# iorx63n register map
Registers are 8-bit, access not given, no defined reset value unless marked. A register's access mark holds for its fields unless they carry their own. Addresses are absolute; registers are grouped by the start of their names; [hi:lo] are bit positions; {n}, {i} and the like mark numbered series; 'fields as' and 'values as' point back to an identical list.

## SFR (part 3 of 4)
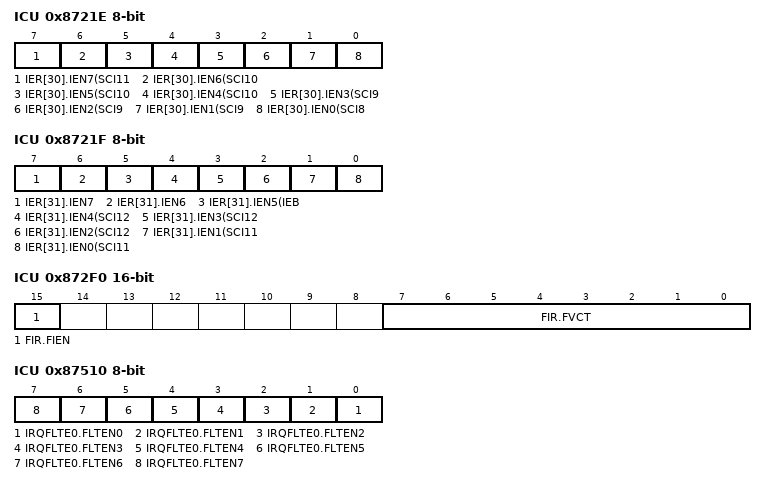
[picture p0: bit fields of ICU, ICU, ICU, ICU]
0x8721E ICU
  [7] IER[30].IEN7(SCI11,RXI11), [6] IER[30].IEN6(SCI10,TEI10), [5] IER[30].IEN5(SCI10,TXI10), [4] IER[30].IEN4(SCI10,RXI10), [3] IER[30].IEN3(SCI9,TEI9), [2] IER[30].IEN2(SCI9,TXI9), [1] IER[30].IEN1(SCI9,RXI9), [0] IER[30].IEN0(SCI8,TEI8)
0x8721F ICU
  [7] IER[31].IEN7, [6] IER[31].IEN6, [5] IER[31].IEN5(IEB,IEBINT), [4] IER[31].IEN4(SCI12,TEI12), [3] IER[31].IEN3(SCI12,TXI12), [2] IER[31].IEN2(SCI12,RXI12), [1] IER[31].IEN1(SCI11,TEI11), [0] IER[31].IEN0(SCI11,TXI11)
0x872E0 ICU
  [0] SWINTR.SWINT
0x872F0 ICU 16-bit
  [15] FIR.FIEN, [7:0] FIR.FVCT
0x87300 ICU
  [3:0] IPR[0](BSC,BUSERR).IPR
0x87301 ICU
  [3:0] IPR[1](FCU,FIFERR).IPR
0x87302 ICU
  [3:0] IPR[2](FCU,FRDYI).IPR
0x87303 ICU
  [3:0] IPR[3](ICU,SWINT).IPR
0x87304 ICU
  [3:0] IPR[4](CMT0,CMI0).IPR
0x87305 ICU
  [3:0] IPR[5](CMT1,CMI1).IPR
0x87306 ICU
  [3:0] IPR[6](CMT2,CMI2).IPR
0x87307 ICU
  [3:0] IPR[7](CMT3,CMI3).IPR
0x87308 ICU
  [3:0] IPR[8].IPR
0x87309 ICU
  [3:0] IPR[9].IPR
0x8730A ICU
  [3:0] IPR[10].IPR
0x8730B ICU
  [3:0] IPR[11].IPR
0x8730C ICU
  [3:0] IPR[12].IPR
0x8730D ICU
  [3:0] IPR[13].IPR
0x8730E ICU
  [3:0] IPR[14].IPR
0x8730F ICU
  [3:0] IPR[15].IPR
0x87310 ICU
  [3:0] IPR[16].IPR
0x87311 ICU
  [3:0] IPR[17].IPR
0x87312 ICU
  [3:0] IPR[18].IPR
0x87313 ICU
  [3:0] IPR[19].IPR
0x87314 ICU
  [3:0] IPR[20].IPR
0x87315 ICU
  [3:0] IPR[21].IPR
0x87316 ICU
  [3:0] IPR[22].IPR
0x87317 ICU
  [3:0] IPR[23].IPR
0x87318 ICU
  [3:0] IPR[24].IPR
0x87319 ICU
  [3:0] IPR[25].IPR
0x8731A ICU
  [3:0] IPR[26].IPR
0x8731B ICU
  [3:0] IPR[27].IPR
0x8731C ICU
  [3:0] IPR[28].IPR
0x8731D ICU
  [3:0] IPR[29].IPR
0x8731E ICU
  [3:0] IPR[30].IPR
0x8731F ICU
  [3:0] IPR[31].IPR
0x87320 ICU
  [3:0] IPR[32](ETHER,EINT).IPR
0x87321 ICU
  [3:0] IPR[33](USB0,D0FIFO0).IPR
0x87322 ICU
  [3:0] IPR[34](USB0,D1FIFO0).IPR
0x87323 ICU
  [3:0] IPR[35](USB0,USBI0).IPR
0x87324 ICU
  [3:0] IPR[36](USB1,D0FIFO1).IPR
0x87325 ICU
  [3:0] IPR[37](USB1,D1FIFO1).IPR
0x87326 ICU
  [3:0] IPR[38](USB1,USBI1).IPR
0x87327 ICU
  [3:0] IPR[39](RSPI0,SPRI0...).IPR
0x87328 ICU
  [3:0] IPR[40].IPR
0x87329 ICU
  [3:0] IPR[41].IPR
0x8732A ICU
  [3:0] IPR[42](RSPI1,SPRI1...).IPR
0x8732B ICU
  [3:0] IPR[43].IPR
0x8732C ICU
  [3:0] IPR[44].IPR
0x8732D ICU
  [3:0] IPR[45](RSPI2,SPRI2...).IPR
0x8732E ICU
  [3:0] IPR[46].IPR
0x8732F ICU
  [3:0] IPR[47].IPR
0x87330 ICU
  [3:0] IPR[48](CAN0,RXF0...).IPR
0x87331 ICU
  [3:0] IPR[49].IPR
0x87332 ICU
  [3:0] IPR[50].IPR
0x87333 ICU
  [3:0] IPR[51].IPR
0x87334 ICU
  [3:0] IPR[52](CAN1,RXF1...).IPR
0x87335 ICU
  [3:0] IPR[53].IPR
0x87336 ICU
  [3:0] IPR[54].IPR
0x87337 ICU
  [3:0] IPR[55].IPR
0x87338 ICU
  [3:0] IPR[56](CAN2,RXF2...).IPR
0x87339 ICU
  [3:0] IPR[57].IPR
0x8733A ICU
  [3:0] IPR[58].IPR
0x8733B ICU
  [3:0] IPR[59].IPR
0x8733C ICU
  [3:0] IPR[60].IPR
0x8733D ICU
  [3:0] IPR[61].IPR
0x8733E ICU
  [3:0] IPR[62](RTC,CUP).IPR
0x8733F ICU
  [3:0] IPR[63].IPR
0x87340 ICU
  [3:0] IPR[64](ICU,IRQ0).IPR
0x87341 ICU
  [3:0] IPR[65](ICU,IRQ1).IPR
0x87342 ICU
  [3:0] IPR[66](ICU,IRQ2).IPR
0x87343 ICU
  [3:0] IPR[67](ICU,IRQ3).IPR
0x87344 ICU
  [3:0] IPR[68](ICU,IRQ4).IPR
0x87345 ICU
  [3:0] IPR[69](ICU,IRQ5).IPR
0x87346 ICU
  [3:0] IPR[70](ICU,IRQ6).IPR
0x87347 ICU
  [3:0] IPR[71](ICU,IRQ7).IPR
0x87348 ICU
  [3:0] IPR[72](ICU,IRQ8).IPR
0x87349 ICU
  [3:0] IPR[73](ICU,IRQ9).IPR
0x8734A ICU
  [3:0] IPR[74](ICU,IRQ10).IPR
0x8734B ICU
  [3:0] IPR[75](ICU,IRQ11).IPR
0x8734C ICU
  [3:0] IPR[76](ICU,IRQ12).IPR
0x8734D ICU
  [3:0] IPR[77](ICU,IRQ13).IPR
0x8734E ICU
  [3:0] IPR[78](ICU,IRQ14).IPR
0x8734F ICU
  [3:0] IPR[79](ICU,IRQ15).IPR
0x87350 ICU
  [3:0] IPR[80].IPR
0x87351 ICU
  [3:0] IPR[81].IPR
0x87352 ICU
  [3:0] IPR[82].IPR
0x87353 ICU
  [3:0] IPR[83].IPR
0x87354 ICU
  [3:0] IPR[84].IPR
0x87355 ICU
  [3:0] IPR[85].IPR
0x87356 ICU
  [3:0] IPR[86].IPR
0x87357 ICU
  [3:0] IPR[87].IPR
0x87358 ICU
  [3:0] IPR[88].IPR
0x87359 ICU
  [3:0] IPR[89].IPR
0x8735A ICU
  [3:0] IPR[90](USB,USBR0).IPR
0x8735B ICU
  [3:0] IPR[91](USB,USBR1).IPR
0x8735C ICU
  [3:0] IPR[92](RTC,ALM).IPR
0x8735D ICU
  [3:0] IPR[93](RTC,PRD).IPR
0x8735E ICU
  [3:0] IPR[94].IPR
0x8735F ICU
  [3:0] IPR[95].IPR
0x87360 ICU
  [3:0] IPR[96].IPR
0x87361 ICU
  [3:0] IPR[97].IPR
0x87362 ICU
  [3:0] IPR[98](AD,ADI0).IPR
0x87363 ICU
  [3:0] IPR[99].IPR
0x87364 ICU
  [3:0] IPR[100].IPR
0x87365 ICU
  [3:0] IPR[101].IPR
0x87366 ICU
  [3:0] IPR[102](S12AD,S12ADI0).IPR
0x87367 ICU
  [3:0] IPR[103].IPR
0x87368 ICU
  [3:0] IPR[104].IPR
0x87369 ICU
  [3:0] IPR[105].IPR
0x8736A ICU
  [3:0] IPR[106](ICU,GROUP0).IPR
0x8736B ICU
  [3:0] IPR[107](ICU,GROUP1).IPR
0x8736C ICU
  [3:0] IPR[108](ICU,GROUP2).IPR
0x8736D ICU
  [3:0] IPR[109](ICU,GROUP3).IPR
0x8736E ICU
  [3:0] IPR[110](ICU,GROUP4).IPR
0x8736F ICU
  [3:0] IPR[111](ICU,GROUP5).IPR
0x87370 ICU
  [3:0] IPR[112](ICU,GROUP6).IPR
0x87371 ICU
  [3:0] IPR[113].IPR
0x87372 ICU
  [3:0] IPR[114](ICU,GROUP12).IPR
0x87373 ICU
  [3:0] IPR[115].IPR
0x87374 ICU
  [3:0] IPR[116].IPR
0x87375 ICU
  [3:0] IPR[117].IPR
0x87376 ICU
  [3:0] IPR[118].IPR
0x87377 ICU
  [3:0] IPR[119].IPR
0x87378 ICU
  [3:0] IPR[120].IPR
0x87379 ICU
  [3:0] IPR[121].IPR
0x8737A ICU
  [3:0] IPR[122](SCI12,SCIX0...).IPR
0x8737B ICU
  [3:0] IPR[123].IPR
0x8737C ICU
  [3:0] IPR[124].IPR
0x8737D ICU
  [3:0] IPR[125].IPR
0x8737E ICU
  [3:0] IPR[126](TPU0,TGI0A...).IPR
0x8737F ICU
  [3:0] IPR[127].IPR
0x87380 ICU
  [3:0] IPR[128].IPR
0x87381 ICU
  [3:0] IPR[129].IPR
0x87382 ICU
  [3:0] IPR[130](TPU1,TGI1A...).IPR
0x87383 ICU
  [3:0] IPR[131].IPR
0x87384 ICU
  [3:0] IPR[132](TPU2,TGI2A...).IPR
0x87385 ICU
  [3:0] IPR[133].IPR
0x87386 ICU
  [3:0] IPR[134](TPU3,TGI3A...).IPR
0x87387 ICU
  [3:0] IPR[135].IPR
0x87388 ICU
  [3:0] IPR[136].IPR
0x87389 ICU
  [3:0] IPR[137].IPR
0x8738A ICU
  [3:0] IPR[138](TPU4,TGI4A...).IPR
0x8738B ICU
  [3:0] IPR[139].IPR
0x8738C ICU
  [3:0] IPR[140](TPU5,TGI5A...).IPR
0x8738D ICU
  [3:0] IPR[141].IPR
0x8738E ICU
  [3:0] IPR[142](TPU6,TGI6A...).IPR
0x8738F ICU
  [3:0] IPR[143].IPR
0x87390 ICU
  [3:0] IPR[144].IPR
0x87391 ICU
  [3:0] IPR[145].IPR
0x87392 ICU
  [3:0] IPR[146](MTU0,TGIE0...).IPR
0x87393 ICU
  [3:0] IPR[147].IPR
0x87394 ICU
  [3:0] IPR[148](TPU7,TGI7A...).IPR
0x87395 ICU
  [3:0] IPR[149].IPR
0x87396 ICU
  [3:0] IPR[150](TPU8,TGI8A...).IPR
0x87397 ICU
  [3:0] IPR[151].IPR
0x87398 ICU
  [3:0] IPR[152](TPU9,TGI9A...).IPR
0x87399 ICU
  [3:0] IPR[153].IPR
0x8739A ICU
  [3:0] IPR[154].IPR
0x8739B ICU
  [3:0] IPR[155].IPR
0x8739C ICU
  [3:0] IPR[156](TPU10,TGI10A...).IPR
0x8739D ICU
  [3:0] IPR[157].IPR
0x8739E ICU
  [3:0] IPR[158].IPR
0x8739F ICU
  [3:0] IPR[159].IPR
0x873A0 ICU
  [3:0] IPR[160](MTU4,TCIV4).IPR
0x873A1 ICU
  [3:0] IPR[161](MTU5,TGIU5...).IPR
0x873A2 ICU
  [3:0] IPR[162].IPR
0x873A3 ICU
  [3:0] IPR[163].IPR
0x873A4 ICU
  [3:0] IPR[164](TPU11,TGI11A...).IPR
0x873A5 ICU
  [3:0] IPR[165].IPR
0x873A6 ICU
  [3:0] IPR[166](POE,OEI1...).IPR
0x873A7 ICU
  [3:0] IPR[167].IPR
0x873A8 ICU
  [3:0] IPR[168].IPR
0x873A9 ICU
  [3:0] IPR[169].IPR
0x873AA ICU
  [3:0] IPR[170](TMR0,CMIA0...).IPR
0x873AB ICU
  [3:0] IPR[171].IPR
0x873AC ICU
  [3:0] IPR[172].IPR
0x873AD ICU
  [3:0] IPR[173](TMR1,CMIA1...).IPR
0x873AE ICU
  [3:0] IPR[174].IPR
0x873AF ICU
  [3:0] IPR[175].IPR
0x873B0 ICU
  [3:0] IPR[176](TMR2,CMIA2...).IPR
0x873B1 ICU
  [3:0] IPR[177].IPR
0x873B2 ICU
  [3:0] IPR[178].IPR
0x873B3 ICU
  [3:0] IPR[179](TMR3,CMIA3...).IPR
0x873B4 ICU
  [3:0] IPR[180].IPR
0x873B5 ICU
  [3:0] IPR[181].IPR
0x873B6 ICU
  [3:0] IPR[182](RIIC0,EEI0).IPR
0x873B7 ICU
  [3:0] IPR[183](RIIC0,RXI0).IPR
0x873B8 ICU
  [3:0] IPR[184](RIIC0,TXI0).IPR
0x873B9 ICU
  [3:0] IPR[185](RIIC0,TEI0).IPR
0x873BA ICU
  [3:0] IPR[186](RIIC1,EEI1).IPR
0x873BB ICU
  [3:0] IPR[187](RIIC1,RXI1).IPR
0x873BC ICU
  [3:0] IPR[188](RIIC1,TXI1).IPR
0x873BD ICU
  [3:0] IPR[189](RIIC1,TEI1).IPR
0x873BE ICU
  [3:0] IPR[190](RIIC2,EEI2).IPR
0x873BF ICU
  [3:0] IPR[191](RIIC2,RXI2).IPR
0x873C0 ICU
  [3:0] IPR[192](RIIC2,TXI2).IPR
0x873C1 ICU
  [3:0] IPR[193](RIIC2,TEI2).IPR
0x873C2 ICU
  [3:0] IPR[194](RIIC3,EEI3).IPR
0x873C3 ICU
  [3:0] IPR[195](RIIC3,RXI3).IPR
0x873C4 ICU
  [3:0] IPR[196](RIIC3,TXI3).IPR
0x873C5 ICU
  [3:0] IPR[197](RIIC3,TEI3).IPR
0x873C6 ICU
  [3:0] IPR[198](DMAC,DMAC0I).IPR
0x873C7 ICU
  [3:0] IPR[199](DMAC,DMAC1I).IPR
0x873C8 ICU
  [3:0] IPR[200](DMAC,DMAC2I).IPR
0x873C9 ICU
  [3:0] IPR[201](DMAC,DMAC3I).IPR
0x873CA ICU
  [3:0] IPR[202](EXDMAC,EXDMAC0I).IPR
0x873CB ICU
  [3:0] IPR[203](EXDMAC,EXDMAC1I).IPR
0x873CC ICU
  [3:0] IPR[204].IPR
0x873CD ICU
  [3:0] IPR[205].IPR
0x873CE ICU
  [3:0] IPR[206].IPR
0x873CF ICU
  [3:0] IPR[207].IPR
0x873D0 ICU
  [3:0] IPR[208].IPR
0x873D1 ICU
  [3:0] IPR[209].IPR
0x873D2 ICU
  [3:0] IPR[210].IPR
0x873D3 ICU
  [3:0] IPR[211].IPR
0x873D4 ICU
  [3:0] IPR[212].IPR
0x873D5 ICU
  [3:0] IPR[213].IPR
0x873D6 ICU
  [3:0] IPR[214](SCI0,RXI0...).IPR
0x873D7 ICU
  [3:0] IPR[215].IPR
0x873D8 ICU
  [3:0] IPR[216].IPR
0x873D9 ICU
  [3:0] IPR[217](SCI1,RXI1...).IPR
0x873DA ICU
  [3:0] IPR[218].IPR
0x873DB ICU
  [3:0] IPR[219].IPR
0x873DC ICU
  [3:0] IPR[220](SCI2,RXI2...).IPR
0x873DD ICU
  [3:0] IPR[221].IPR
0x873DE ICU
  [3:0] IPR[222].IPR
0x873DF ICU
  [3:0] IPR[223](SCI3,RXI3...).IPR
0x873E0 ICU
  [3:0] IPR[224].IPR
0x873E1 ICU
  [3:0] IPR[225].IPR
0x873E2 ICU
  [3:0] IPR[226](SCI4,RXI4...).IPR
0x873E3 ICU
  [3:0] IPR[227].IPR
0x873E4 ICU
  [3:0] IPR[228].IPR
0x873E5 ICU
  [3:0] IPR[229](SCI5,RXI5...).IPR
0x873E6 ICU
  [3:0] IPR[230].IPR
0x873E7 ICU
  [3:0] IPR[231].IPR
0x873E8 ICU
  [3:0] IPR[232](SCI6,RXI6...).IPR
0x873E9 ICU
  [3:0] IPR[233].IPR
0x873EA ICU
  [3:0] IPR[234].IPR
0x873EB ICU
  [3:0] IPR[235](SCI7,RXI7...).IPR
0x873EC ICU
  [3:0] IPR[236].IPR
0x873ED ICU
  [3:0] IPR[237].IPR
0x873EE ICU
  [3:0] IPR[238](SCI8,RXI8...).IPR
0x873EF ICU
  [3:0] IPR[239].IPR
0x873F0 ICU
  [3:0] IPR[240].IPR
0x873F1 ICU
  [3:0] IPR[241](SCI9,RXI9...).IPR
0x873F2 ICU
  [3:0] IPR[242].IPR
0x873F3 ICU
  [3:0] IPR[243].IPR
0x873F4 ICU
  [3:0] IPR[244](SCI10,RXI10...).IPR
0x873F5 ICU
  [3:0] IPR[245].IPR
0x873F6 ICU
  [3:0] IPR[246].IPR
0x873F7 ICU
  [3:0] IPR[247](SCI11,RXI11...).IPR
0x873F8 ICU
  [3:0] IPR[248].IPR
0x873F9 ICU
  [3:0] IPR[249].IPR
0x873FA ICU
  [3:0] IPR[250](SCI12,RXI12...).IPR
0x873FB ICU
  [3:0] IPR[251].IPR
0x873FC ICU
  [3:0] IPR[252].IPR
0x873FD ICU
  [3:0] IPR[253](IEB,IEBINT).IPR
0x87400 ICU
  [7:0] DMRSR0.DMRS
0x87404 ICU
  [7:0] DMRSR1.DMRS
0x87408 ICU
  [7:0] DMRSR2.DMRS
0x8740C ICU
  [7:0] DMRSR3.DMRS
0x87500 ICU
  [3:2] IRQCR[0].IRQMD
0x87501 ICU
  [3:2] IRQCR[1].IRQMD
0x87502 ICU
  [3:2] IRQCR[2].IRQMD
0x87503 ICU
  [3:2] IRQCR[3].IRQMD
0x87504 ICU
  [3:2] IRQCR[4].IRQMD
0x87505 ICU
  [3:2] IRQCR[5].IRQMD
0x87506 ICU
  [3:2] IRQCR[6].IRQMD
0x87507 ICU
  [3:2] IRQCR[7].IRQMD
0x87508 ICU
  [3:2] IRQCR[8].IRQMD
0x87509 ICU
  [3:2] IRQCR[9].IRQMD
0x8750A ICU
  [3:2] IRQCR[10].IRQMD
0x8750B ICU
  [3:2] IRQCR[11].IRQMD
0x8750C ICU
  [3:2] IRQCR[12].IRQMD
0x8750D ICU
  [3:2] IRQCR[13].IRQMD
0x8750E ICU
  [3:2] IRQCR[14].IRQMD
0x8750F ICU
  [3:2] IRQCR[15].IRQMD
0x87510 ICU
  [n] IRQFLTE0.FLTEN{n} (n=0..7)
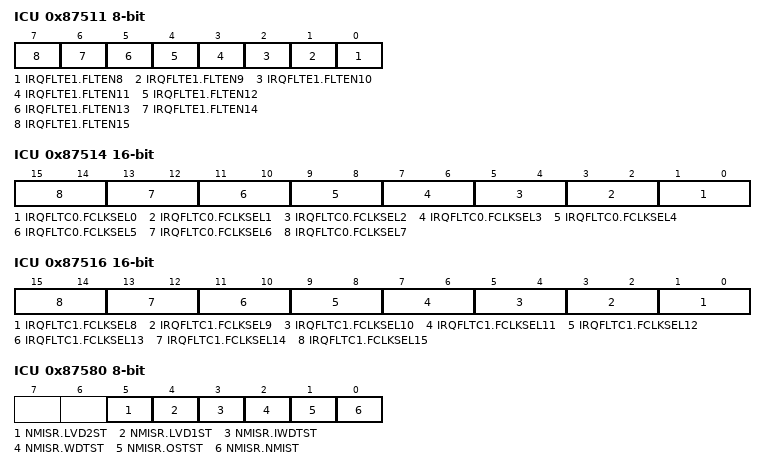
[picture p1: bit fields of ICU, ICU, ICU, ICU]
0x87511 ICU
  [n-8] IRQFLTE1.FLTEN{n} (n=8..15)
0x87514 ICU 16-bit
  [2n+1:2n] IRQFLTC0.FCLKSEL{n} (n=0..7)
0x87516 ICU 16-bit
  [2n-15:2n-16] IRQFLTC1.FCLKSEL{n} (n=8..15)
0x87580 ICU
  [5] NMISR.LVD2ST, [4] NMISR.LVD1ST, [3] NMISR.IWDTST, [2] NMISR.WDTST, [1] NMISR.OSTST, [0] NMISR.NMIST
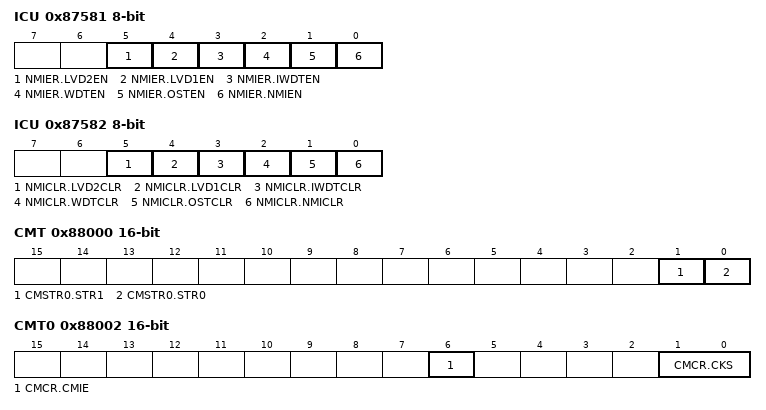
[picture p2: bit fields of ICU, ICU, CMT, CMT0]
0x87581 ICU
  [5] NMIER.LVD2EN, [4] NMIER.LVD1EN, [3] NMIER.IWDTEN, [2] NMIER.WDTEN, [1] NMIER.OSTEN, [0] NMIER.NMIEN
0x87582 ICU
  [5] NMICLR.LVD2CLR, [4] NMICLR.LVD1CLR, [3] NMICLR.IWDTCLR, [2] NMICLR.WDTCLR, [1] NMICLR.OSTCLR, [0] NMICLR.NMICLR
0x87583 ICU
  [3] NMICR.NMIMD
0x87590 ICU
  [0] NMIFLTE.NFLTEN
0x87594 ICU
  [1:0] NMIFLTC.NFCLKSEL
0x88000 CMT 16-bit
  [1] CMSTR0.STR1, [0] CMSTR0.STR0
0x88002 CMT0 16-bit
  [6] CMCR.CMIE, [1:0] CMCR.CKS
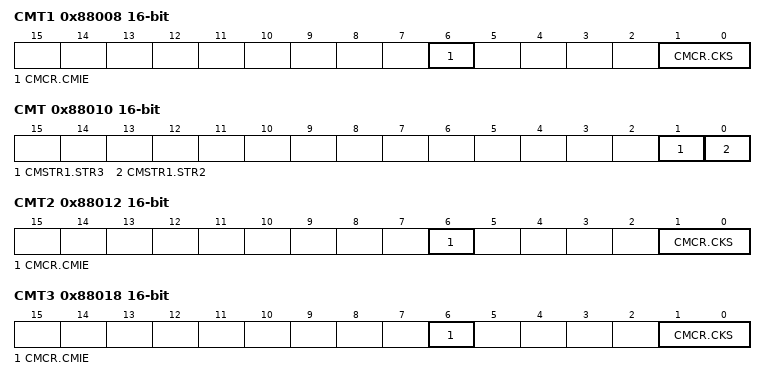
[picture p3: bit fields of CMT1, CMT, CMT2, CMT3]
0x88008 CMT1 16-bit
  [6] CMCR.CMIE, [1:0] CMCR.CKS
0x88010 CMT 16-bit
  [1] CMSTR1.STR3, [0] CMSTR1.STR2
0x88012 CMT2 16-bit
  [6] CMCR.CMIE, [1:0] CMCR.CKS
0x88018 CMT3 16-bit
  [6] CMCR.CMIE, [1:0] CMCR.CKS
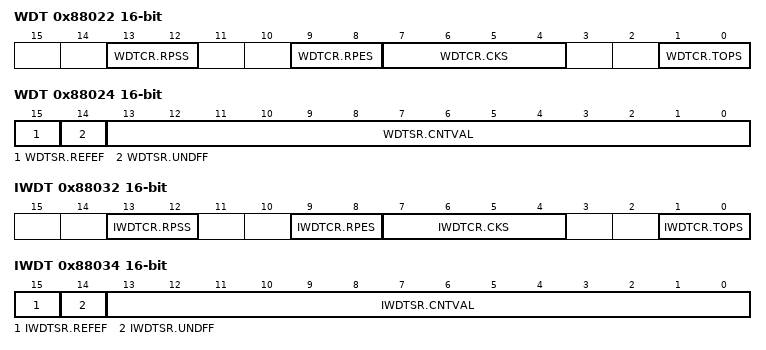
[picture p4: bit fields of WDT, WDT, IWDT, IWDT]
0x88022 WDT 16-bit
  [13:12] WDTCR.RPSS, [9:8] WDTCR.RPES, [7:4] WDTCR.CKS, [1:0] WDTCR.TOPS
0x88024 WDT 16-bit
  [15] WDTSR.REFEF, [14] WDTSR.UNDFF, [13:0] WDTSR.CNTVAL
0x88026 WDT
  [7] WDTRCR.RSTIRQS
0x88032 IWDT 16-bit
  [13:12] IWDTCR.RPSS, [9:8] IWDTCR.RPES, [7:4] IWDTCR.CKS, [1:0] IWDTCR.TOPS
0x88034 IWDT 16-bit
  [15] IWDTSR.REFEF, [14] IWDTSR.UNDFF, [13:0] IWDTSR.CNTVAL
0x88036 IWDT
  [7] IWDTRCR.RSTIRQS
0x88038 IWDT
  [7] IWDTCSTPR.SLCSTP
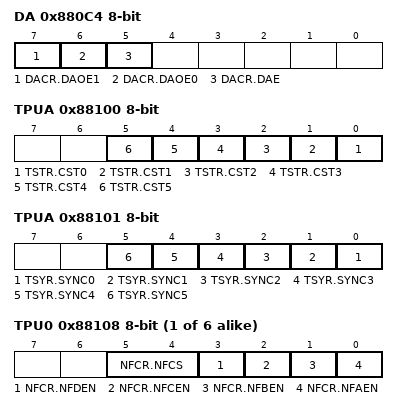
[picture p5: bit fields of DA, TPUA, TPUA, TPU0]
0x880C4 DA
  [7] DACR.DAOE1, [6] DACR.DAOE0, [5] DACR.DAE
0x880C5 DA
  [7] DADPR.DPSEL
0x880C6 DA
  [7] DAADSCR.DAADST
0x88100 TPUA
  [n] TSTR.CST{n} (n=0..5)
0x88101 TPUA
  [n] TSYR.SYNC{n} (n=0..5)
{0x88108+i} TPU{i} (i=0..5)
  [5:4] NFCR.NFCS, [3] NFCR.NFDEN, [2] NFCR.NFCEN, [1] NFCR.NFBEN, [0] NFCR.NFAEN
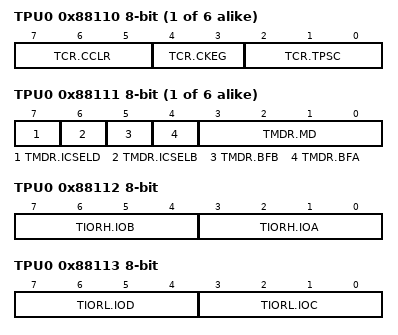
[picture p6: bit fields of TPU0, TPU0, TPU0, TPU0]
{0x88110+0x10*i} TPU{i} (i=0..5)
  [7:5] TCR.CCLR, [4:3] TCR.CKEG, [2:0] TCR.TPSC
{0x88111+0x10*i} TPU{i} (i=0..5)
  [7] TMDR.ICSELD, [6] TMDR.ICSELB, [5] TMDR.BFB, [4] TMDR.BFA, [3:0] TMDR.MD
0x88112 TPU0
  [7:4] TIORH.IOB, [3:0] TIORH.IOA
0x88113 TPU0
  [7:4] TIORL.IOD, [3:0] TIORL.IOC
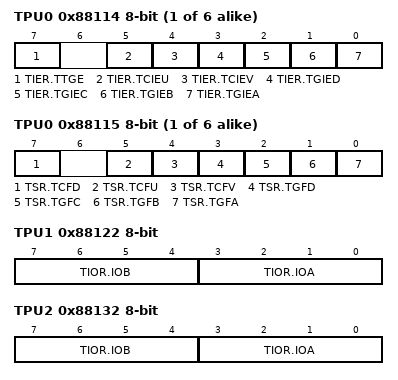
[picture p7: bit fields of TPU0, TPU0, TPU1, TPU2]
{0x88114+0x10*i} TPU{i} (i=0..5)
  [7] TIER.TTGE, [5] TIER.TCIEU, [4] TIER.TCIEV, [3] TIER.TGIED, [2] TIER.TGIEC, [1] TIER.TGIEB, [0] TIER.TGIEA
{0x88115+0x10*i} TPU{i} (i=0..5)
  [7] TSR.TCFD, [5] TSR.TCFU, [4] TSR.TCFV, [3] TSR.TGFD, [2] TSR.TGFC, [1] TSR.TGFB, [0] TSR.TGFA
0x88122 TPU1
  [7:4] TIOR.IOB, [3:0] TIOR.IOA
0x88132 TPU2
  [7:4] TIOR.IOB, [3:0] TIOR.IOA
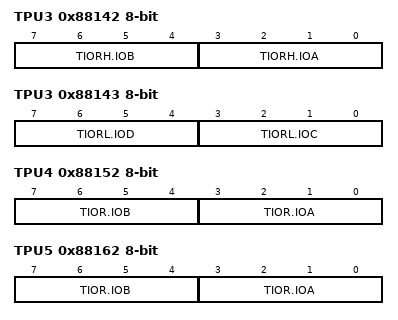
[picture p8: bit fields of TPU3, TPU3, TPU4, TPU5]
0x88142 TPU3
  [7:4] TIORH.IOB, [3:0] TIORH.IOA
0x88143 TPU3
  [7:4] TIORL.IOD, [3:0] TIORL.IOC
0x88152 TPU4
  [7:4] TIOR.IOB, [3:0] TIOR.IOA
0x88162 TPU5
  [7:4] TIOR.IOB, [3:0] TIOR.IOA
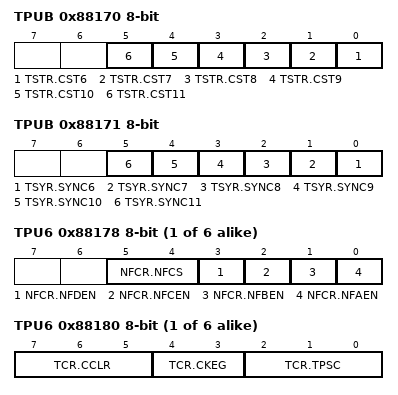
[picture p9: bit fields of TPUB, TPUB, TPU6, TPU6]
0x88170 TPUB
  [n-6] TSTR.CST{n} (n=6..11)
0x88171 TPUB
  [n-6] TSYR.SYNC{n} (n=6..11)
{0x88172+i} TPU{i} (i=6..11)
  fields as TPU0
{0x88120+0x10*i} TPU{i} (i=6..11)
  [7:5] TCR.CCLR, [4:3] TCR.CKEG, [2:0] TCR.TPSC
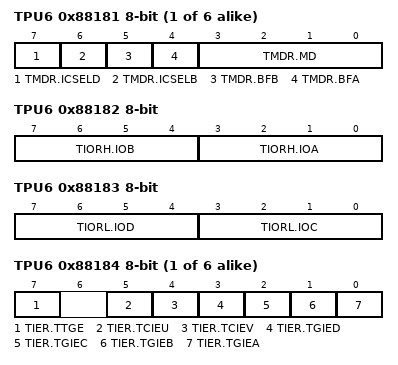
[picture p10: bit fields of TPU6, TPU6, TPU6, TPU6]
{0x88121+0x10*i} TPU{i} (i=6..11)
  [7] TMDR.ICSELD, [6] TMDR.ICSELB, [5] TMDR.BFB, [4] TMDR.BFA, [3:0] TMDR.MD
0x88182 TPU6
  [7:4] TIORH.IOB, [3:0] TIORH.IOA
0x88183 TPU6
  [7:4] TIORL.IOD, [3:0] TIORL.IOC
{0x88124+0x10*i} TPU{i} (i=6..11)
  [7] TIER.TTGE, [5] TIER.TCIEU, [4] TIER.TCIEV, [3] TIER.TGIED, [2] TIER.TGIEC, [1] TIER.TGIEB, [0] TIER.TGIEA
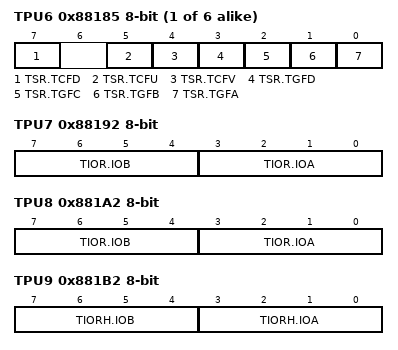
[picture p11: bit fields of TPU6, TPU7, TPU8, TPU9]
{0x88125+0x10*i} TPU{i} (i=6..11)
  [7] TSR.TCFD, [5] TSR.TCFU, [4] TSR.TCFV, [3] TSR.TGFD, [2] TSR.TGFC, [1] TSR.TGFB, [0] TSR.TGFA
0x88192 TPU7
  [7:4] TIOR.IOB, [3:0] TIOR.IOA
0x881A2 TPU8
  [7:4] TIOR.IOB, [3:0] TIOR.IOA
0x881B2 TPU9
  [7:4] TIORH.IOB, [3:0] TIORH.IOA
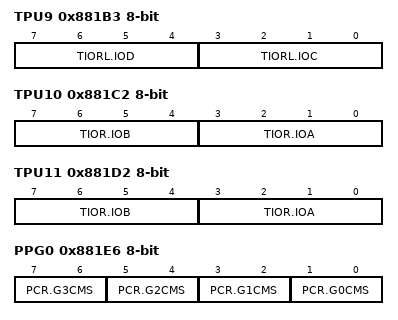
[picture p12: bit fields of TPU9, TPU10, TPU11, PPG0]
0x881B3 TPU9
  [7:4] TIORL.IOD, [3:0] TIORL.IOC
0x881C2 TPU10
  [7:4] TIOR.IOB, [3:0] TIOR.IOA
0x881D2 TPU11
  [7:4] TIOR.IOB, [3:0] TIOR.IOA
0x881E6 PPG0
  [2n+1:2n] PCR.G{n}CMS (n=0..3)
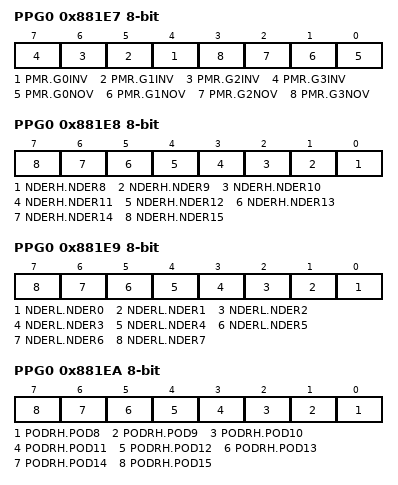
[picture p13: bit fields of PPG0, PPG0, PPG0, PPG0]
0x881E7 PPG0
  [n+4] PMR.G{n}INV (n=0..3), [n] PMR.G{n}NOV (n=0..3)
0x881E8 PPG0
  [n-8] NDERH.NDER{n} (n=8..15)
0x881E9 PPG0
  [n] NDERL.NDER{n} (n=0..7)
0x881EA PPG0
  [n-8] PODRH.POD{n} (n=8..15)
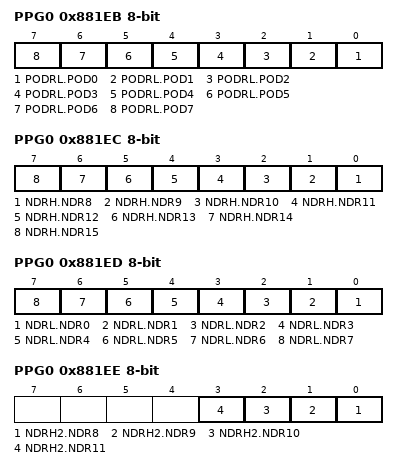
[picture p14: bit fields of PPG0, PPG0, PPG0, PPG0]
0x881EB PPG0
  [n] PODRL.POD{n} (n=0..7)
0x881EC PPG0
  [n-8] NDRH.NDR{n} (n=8..15)
0x881ED PPG0
  [n] NDRL.NDR{n} (n=0..7)
0x881EE PPG0
  [n-8] NDRH2.NDR{n} (n=8..11)
0x881EF PPG0
  [n] NDRL2.NDR{n} (n=0..3)
0x881F0 PPG1
  [0] PTRSLR.PTRSL
0x881F6 PPG1
  [2n+1:2n] PCR.G{n}CMS (n=0..3)
0x881F7 PPG1
  [n+4] PMR.G{n}INV (n=0..3), [n] PMR.G{n}NOV (n=0..3)
0x881F8 PPG1
  [n-24] NDERH.NDER{n} (n=24..31)
0x881F9 PPG1
  [n-16] NDERL.NDER{n} (n=16..23)
0x881FA PPG1
  [n-24] PODRH.POD{n} (n=24..31)
0x881FB PPG1
  [n-16] PODRL.POD{n} (n=16..23)
0x881FC PPG1
  [n-24] NDRH.NDR{n} (n=24..31)
0x881FD PPG1
  [n-16] NDRL.NDR{n} (n=16..23)
0x881FE PPG1
  [n-24] NDRH2.NDR{n} (n=24..27)
0x881FF PPG1
  [n-16] NDRL2.NDR{n} (n=16..19)
0x88200 TMR0
  [7] TCR.CMIEB, [6] TCR.CMIEA, [5] TCR.OVIE, [4:3] TCR.CCLR
0x88201 TMR1
  [7] TCR.CMIEB, [6] TCR.CMIEA, [5] TCR.OVIE, [4:3] TCR.CCLR
0x88202 TMR0
  [4] TCSR.ADTE, [3:2] TCSR.OSB, [1:0] TCSR.OSA
0x88203 TMR1
  [3:2] TCSR.OSB, [1:0] TCSR.OSA
0x8820A TMR0
  [7] TCCR.TMRIS, [4:3] TCCR.CSS, [2:0] TCCR.CKS
0x8820B TMR1
  [7] TCCR.TMRIS, [4:3] TCCR.CSS, [2:0] TCCR.CKS
0x88210 TMR2
  [7] TCR.CMIEB, [6] TCR.CMIEA, [5] TCR.OVIE, [4:3] TCR.CCLR
0x88211 TMR3
  [7] TCR.CMIEB, [6] TCR.CMIEA, [5] TCR.OVIE, [4:3] TCR.CCLR
0x88212 TMR2
  [4] TCSR.ADTE, [3:2] TCSR.OSB, [1:0] TCSR.OSA
0x88213 TMR3
  [3:2] TCSR.OSB, [1:0] TCSR.OSA
0x8821A TMR2
  [7] TCCR.TMRIS, [4:3] TCCR.CSS, [2:0] TCCR.CKS
0x8821B TMR3
  [7] TCCR.TMRIS, [4:3] TCCR.CSS, [2:0] TCCR.CKS
0x88280 CRC
  [7] CRCCR.DORCLR, [2] CRCCR.LMS, [1:0] CRCCR.GPS
{0x88300+0x20*i} RIIC{i} (i=0..3)
  [7] ICCR1.ICE, [6] ICCR1.IICRST, [5] ICCR1.CLO, [4] ICCR1.SOWP, [3] ICCR1.SCLO, [2] ICCR1.SDAO, [1] ICCR1.SCLI, [0] ICCR1.SDAI
{0x88301+0x20*i} RIIC{i} (i=0..3)
  [7] ICCR2.BBSY, [6] ICCR2.MST, [5] ICCR2.TRS, [3] ICCR2.SP, [2] ICCR2.RS, [1] ICCR2.ST
{0x88302+0x20*i} RIIC{i} (i=0..3)
  [7] ICMR1.MTWP, [6:4] ICMR1.CKS, [3] ICMR1.BCWP, [2:0] ICMR1.BC
{0x88303+0x20*i} RIIC{i} (i=0..3)
  [7] ICMR2.DLCS, [6:4] ICMR2.SDDL, [3] ICMR2.TMWE, [2] ICMR2.TMOH, [1] ICMR2.TMOL, [0] ICMR2.TMOS
{0x88304+0x20*i} RIIC{i} (i=0..3)
  [7] ICMR3.SMBS, [6] ICMR3.WAIT, [5] ICMR3.RDRFS, [4] ICMR3.ACKWP, [3] ICMR3.ACKBT, [2] ICMR3.ACKBR, [1:0] ICMR3.NF
0x88305 RIIC0
  [7] ICFER.FMPE, [6] ICFER.SCLE, [5] ICFER.NFE, [4] ICFER.NACKE, [3] ICFER.SALE, [2] ICFER.NALE, [1] ICFER.MALE, [0] ICFER.TMOE
{0x88306+0x20*i} RIIC{i} (i=0..3)
  [7] ICSER.HOAE, [5] ICSER.DIDE, [3] ICSER.GCAE, [2] ICSER.SAR2E, [1] ICSER.SAR1E, [0] ICSER.SAR0E
{0x88307+0x20*i} RIIC{i} (i=0..3)
  [7] ICIER.TIE, [6] ICIER.TEIE, [5] ICIER.RIE, [4] ICIER.NAKIE, [3] ICIER.SPIE, [2] ICIER.STIE, [1] ICIER.ALIE, [0] ICIER.TMOIE
{0x88308+0x20*i} RIIC{i} (i=0..3)
  [7] ICSR1.HOA, [5] ICSR1.DID, [3] ICSR1.GCA, [2] ICSR1.AAS2, [1] ICSR1.AAS1, [0] ICSR1.AAS0
{0x88309+0x20*i} RIIC{i} (i=0..3)
  [7] ICSR2.TDRE, [6] ICSR2.TEND, [5] ICSR2.RDRF, [4] ICSR2.NACKF, [3] ICSR2.STOP, [2] ICSR2.START, [1] ICSR2.AL, [0] ICSR2.TMOF
0x8830A RIIC0
  [7:1] SARL0.SVA, [0] SARL0.SVA0
0x8830B RIIC0
  [2:1] SARU0.SVA, [0] SARU0.FS
0x8830C RIIC0
  [7:1] SARL1.SVA, [0] SARL1.SVA0
0x8830D RIIC0
  [2:1] SARU1.SVA, [0] SARU1.FS
0x8830E RIIC0
  [7:1] SARL2.SVA, [0] SARL2.SVA0
0x8830F RIIC0
  [2:1] SARU2.SVA, [0] SARU2.FS
{0x88310+0x20*i} RIIC{i} (i=0..3)
  [4:0] ICBRL.BRL
{0x88311+0x20*i} RIIC{i} (i=0..3)
  [4:0] ICBRH.BRH
{0x88305+0x20*i} RIIC{i} (i=1..3)
  [6] ICFER.SCLE, [5] ICFER.NFE, [4] ICFER.NACKE, [3] ICFER.SALE, [2] ICFER.NALE, [1] ICFER.MALE, [0] ICFER.TMOE
0x8832A RIIC1
  [7:1] SARL0.SVA, [0] SARL0.SVA0
0x8832B RIIC1
  [2:1] SARU0.SVA, [0] SARU0.FS
0x8832C RIIC1
  [7:1] SARL1.SVA, [0] SARL1.SVA0
0x8832D RIIC1
  [2:1] SARU1.SVA, [0] SARU1.FS
0x8832E RIIC1
  [7:1] SARL2.SVA, [0] SARL2.SVA0
0x8832F RIIC1
  [2:1] SARU2.SVA, [0] SARU2.FS
0x8834A RIIC2
  [7:1] SARL0.SVA, [0] SARL0.SVA0
0x8834B RIIC2
  [2:1] SARU0.SVA, [0] SARU0.FS
0x8834C RIIC2
  [7:1] SARL1.SVA, [0] SARL1.SVA0
0x8834D RIIC2
  [2:1] SARU1.SVA, [0] SARU1.FS
0x8834E RIIC2
  [7:1] SARL2.SVA, [0] SARL2.SVA0
0x8834F RIIC2
  [2:1] SARU2.SVA, [0] SARU2.FS
0x8836A RIIC3
  [7:1] SARL0.SVA, [0] SARL0.SVA0
0x8836B RIIC3
  [2:1] SARU0.SVA, [0] SARU0.FS
0x8836C RIIC3
  [7:1] SARL1.SVA, [0] SARL1.SVA0
0x8836D RIIC3
  [2:1] SARU1.SVA, [0] SARU1.FS
0x8836E RIIC3
  [7:1] SARL2.SVA, [0] SARL2.SVA0
0x8836F RIIC3
  [2:1] SARU2.SVA, [0] SARU2.FS
{0x88380+0x20*i} RSPI{i} (i=0..2)
  [7] SPCR.SPRIE, [6] SPCR.SPE, [5] SPCR.SPTIE, [4] SPCR.SPEIE, [3] SPCR.MSTR, [2] SPCR.MODFEN, [1] SPCR.TXMD, [0] SPCR.SPMS
{0x88381+0x20*i} RSPI{i} (i=0..2)
  [n] SSLP.SSL{n}P (n=0..3)
{0x88382+0x20*i} RSPI{i} (i=0..2)
  [5] SPPCR.MOIFE, [4] SPPCR.MOIFV, [1] SPPCR.SPLP2, [0] SPPCR.SPLP
{0x88383+0x20*i} RSPI{i} (i=0..2)
  [3] SPSR.PERF, [2] SPSR.MODF, [1] SPSR.IDLNF, [0] SPSR.OVRF
{0x88384+0x20*i} RSPI{i} 32-bit (i=0..2)
  [31:16] SPDR.H
{0x88388+0x20*i} RSPI{i} (i=0..2)
  [2:0] SPSCR.SPSLN
{0x88389+0x20*i} RSPI{i} (i=0..2)
  [6:4] SPSSR.SPECM, [2:0] SPSSR.SPCP
{0x8838B+0x20*i} RSPI{i} (i=0..2)
  [5] SPDCR.SPLW, [4] SPDCR.SPRDTD, [1:0] SPDCR.SPFC
{0x8838C+0x20*i} RSPI{i} (i=0..2)
  [2:0] SPCKD.SCKDL
{0x8838D+0x20*i} RSPI{i} (i=0..2)
  [2:0] SSLND.SLNDL
{0x8838E+0x20*i} RSPI{i} (i=0..2)
  [2:0] SPND.SPNDL
{0x8838F+0x20*i} RSPI{i} (i=0..2)
  [3] SPCR2.PTE, [2] SPCR2.SPIIE, [1] SPCR2.SPOE, [0] SPCR2.SPPE
0x88390 RSPI0 16-bit
  [15] SPCMD0.SCKDEN, [14] SPCMD0.SLNDEN, [13] SPCMD0.SPNDEN, [12] SPCMD0.LSBF, [11:8] SPCMD0.SPB, [7] SPCMD0.SSLKP, [6:4] SPCMD0.SSLA, [3:2] SPCMD0.BRDV, [1] SPCMD0.CPOL, [0] SPCMD0.CPHA
0x88392 RSPI0 16-bit
  [15] SPCMD1.SCKDEN, [14] SPCMD1.SLNDEN, [13] SPCMD1.SPNDEN, [12] SPCMD1.LSBF, [11:8] SPCMD1.SPB, [7] SPCMD1.SSLKP, [6:4] SPCMD1.SSLA, [3:2] SPCMD1.BRDV, [1] SPCMD1.CPOL, [0] SPCMD1.CPHA
0x88394 RSPI0 16-bit
  [15] SPCMD2.SCKDEN, [14] SPCMD2.SLNDEN, [13] SPCMD2.SPNDEN, [12] SPCMD2.LSBF, [11:8] SPCMD2.SPB, [7] SPCMD2.SSLKP, [6:4] SPCMD2.SSLA, [3:2] SPCMD2.BRDV, [1] SPCMD2.CPOL, [0] SPCMD2.CPHA
0x88396 RSPI0 16-bit
  [15] SPCMD3.SCKDEN, [14] SPCMD3.SLNDEN, [13] SPCMD3.SPNDEN, [12] SPCMD3.LSBF, [11:8] SPCMD3.SPB, [7] SPCMD3.SSLKP, [6:4] SPCMD3.SSLA, [3:2] SPCMD3.BRDV, [1] SPCMD3.CPOL, [0] SPCMD3.CPHA
0x88398 RSPI0 16-bit
  [15] SPCMD4.SCKDEN, [14] SPCMD4.SLNDEN, [13] SPCMD4.SPNDEN, [12] SPCMD4.LSBF, [11:8] SPCMD4.SPB, [7] SPCMD4.SSLKP, [6:4] SPCMD4.SSLA, [3:2] SPCMD4.BRDV, [1] SPCMD4.CPOL, [0] SPCMD4.CPHA
0x8839A RSPI0 16-bit
  [15] SPCMD5.SCKDEN, [14] SPCMD5.SLNDEN, [13] SPCMD5.SPNDEN, [12] SPCMD5.LSBF, [11:8] SPCMD5.SPB, [7] SPCMD5.SSLKP, [6:4] SPCMD5.SSLA, [3:2] SPCMD5.BRDV, [1] SPCMD5.CPOL, [0] SPCMD5.CPHA
0x8839C RSPI0 16-bit
  [15] SPCMD6.SCKDEN, [14] SPCMD6.SLNDEN, [13] SPCMD6.SPNDEN, [12] SPCMD6.LSBF, [11:8] SPCMD6.SPB, [7] SPCMD6.SSLKP, [6:4] SPCMD6.SSLA, [3:2] SPCMD6.BRDV, [1] SPCMD6.CPOL, [0] SPCMD6.CPHA
0x8839E RSPI0 16-bit
  [15] SPCMD7.SCKDEN, [14] SPCMD7.SLNDEN, [13] SPCMD7.SPNDEN, [12] SPCMD7.LSBF, [11:8] SPCMD7.SPB, [7] SPCMD7.SSLKP, [6:4] SPCMD7.SSLA, [3:2] SPCMD7.BRDV, [1] SPCMD7.CPOL, [0] SPCMD7.CPHA
0x883B0 RSPI1 16-bit
  [15] SPCMD0.SCKDEN, [14] SPCMD0.SLNDEN, [13] SPCMD0.SPNDEN, [12] SPCMD0.LSBF, [11:8] SPCMD0.SPB, [7] SPCMD0.SSLKP, [6:4] SPCMD0.SSLA, [3:2] SPCMD0.BRDV, [1] SPCMD0.CPOL, [0] SPCMD0.CPHA
0x883B2 RSPI1 16-bit
  [15] SPCMD1.SCKDEN, [14] SPCMD1.SLNDEN, [13] SPCMD1.SPNDEN, [12] SPCMD1.LSBF, [11:8] SPCMD1.SPB, [7] SPCMD1.SSLKP, [6:4] SPCMD1.SSLA, [3:2] SPCMD1.BRDV, [1] SPCMD1.CPOL, [0] SPCMD1.CPHA
0x883B4 RSPI1 16-bit
  [15] SPCMD2.SCKDEN, [14] SPCMD2.SLNDEN, [13] SPCMD2.SPNDEN, [12] SPCMD2.LSBF, [11:8] SPCMD2.SPB, [7] SPCMD2.SSLKP, [6:4] SPCMD2.SSLA, [3:2] SPCMD2.BRDV, [1] SPCMD2.CPOL, [0] SPCMD2.CPHA
0x883B6 RSPI1 16-bit
  [15] SPCMD3.SCKDEN, [14] SPCMD3.SLNDEN, [13] SPCMD3.SPNDEN, [12] SPCMD3.LSBF, [11:8] SPCMD3.SPB, [7] SPCMD3.SSLKP, [6:4] SPCMD3.SSLA, [3:2] SPCMD3.BRDV, [1] SPCMD3.CPOL, [0] SPCMD3.CPHA
0x883B8 RSPI1 16-bit
  [15] SPCMD4.SCKDEN, [14] SPCMD4.SLNDEN, [13] SPCMD4.SPNDEN, [12] SPCMD4.LSBF, [11:8] SPCMD4.SPB, [7] SPCMD4.SSLKP, [6:4] SPCMD4.SSLA, [3:2] SPCMD4.BRDV, [1] SPCMD4.CPOL, [0] SPCMD4.CPHA
0x883BA RSPI1 16-bit
  [15] SPCMD5.SCKDEN, [14] SPCMD5.SLNDEN, [13] SPCMD5.SPNDEN, [12] SPCMD5.LSBF, [11:8] SPCMD5.SPB, [7] SPCMD5.SSLKP, [6:4] SPCMD5.SSLA, [3:2] SPCMD5.BRDV, [1] SPCMD5.CPOL, [0] SPCMD5.CPHA
0x883BC RSPI1 16-bit
  [15] SPCMD6.SCKDEN, [14] SPCMD6.SLNDEN, [13] SPCMD6.SPNDEN, [12] SPCMD6.LSBF, [11:8] SPCMD6.SPB, [7] SPCMD6.SSLKP, [6:4] SPCMD6.SSLA, [3:2] SPCMD6.BRDV, [1] SPCMD6.CPOL, [0] SPCMD6.CPHA
0x883BE RSPI1 16-bit
  [15] SPCMD7.SCKDEN, [14] SPCMD7.SLNDEN, [13] SPCMD7.SPNDEN, [12] SPCMD7.LSBF, [11:8] SPCMD7.SPB, [7] SPCMD7.SSLKP, [6:4] SPCMD7.SSLA, [3:2] SPCMD7.BRDV, [1] SPCMD7.CPOL, [0] SPCMD7.CPHA
0x883D0 RSPI2 16-bit
  fields as RSPI1
0x883D2 RSPI2 16-bit
  [15] SPCMD1.SCKDEN, [14] SPCMD1.SLNDEN, [13] SPCMD1.SPNDEN, [12] SPCMD1.LSBF, [11:8] SPCMD1.SPB, [7] SPCMD1.SSLKP, [6:4] SPCMD1.SSLA, [3:2] SPCMD1.BRDV, [1] SPCMD1.CPOL, [0] SPCMD1.CPHA
0x883D4 RSPI2 16-bit
  [15] SPCMD2.SCKDEN, [14] SPCMD2.SLNDEN, [13] SPCMD2.SPNDEN, [12] SPCMD2.LSBF, [11:8] SPCMD2.SPB, [7] SPCMD2.SSLKP, [6:4] SPCMD2.SSLA, [3:2] SPCMD2.BRDV, [1] SPCMD2.CPOL, [0] SPCMD2.CPHA
0x883D6 RSPI2 16-bit
  [15] SPCMD3.SCKDEN, [14] SPCMD3.SLNDEN, [13] SPCMD3.SPNDEN, [12] SPCMD3.LSBF, [11:8] SPCMD3.SPB, [7] SPCMD3.SSLKP, [6:4] SPCMD3.SSLA, [3:2] SPCMD3.BRDV, [1] SPCMD3.CPOL, [0] SPCMD3.CPHA
0x883D8 RSPI2 16-bit
  [15] SPCMD4.SCKDEN, [14] SPCMD4.SLNDEN, [13] SPCMD4.SPNDEN, [12] SPCMD4.LSBF, [11:8] SPCMD4.SPB, [7] SPCMD4.SSLKP, [6:4] SPCMD4.SSLA, [3:2] SPCMD4.BRDV, [1] SPCMD4.CPOL, [0] SPCMD4.CPHA
0x883DA RSPI2 16-bit
  [15] SPCMD5.SCKDEN, [14] SPCMD5.SLNDEN, [13] SPCMD5.SPNDEN, [12] SPCMD5.LSBF, [11:8] SPCMD5.SPB, [7] SPCMD5.SSLKP, [6:4] SPCMD5.SSLA, [3:2] SPCMD5.BRDV, [1] SPCMD5.CPOL, [0] SPCMD5.CPHA
0x883DC RSPI2 16-bit
  [15] SPCMD6.SCKDEN, [14] SPCMD6.SLNDEN, [13] SPCMD6.SPNDEN, [12] SPCMD6.LSBF, [11:8] SPCMD6.SPB, [7] SPCMD6.SSLKP, [6:4] SPCMD6.SSLA, [3:2] SPCMD6.BRDV, [1] SPCMD6.CPOL, [0] SPCMD6.CPHA
0x883DE RSPI2 16-bit
  [15] SPCMD7.SCKDEN, [14] SPCMD7.SLNDEN, [13] SPCMD7.SPNDEN, [12] SPCMD7.LSBF, [11:8] SPCMD7.SPB, [7] SPCMD7.SSLKP, [6:4] SPCMD7.SSLA, [3:2] SPCMD7.BRDV, [1] SPCMD7.CPOL, [0] SPCMD7.CPHA
0x88600 MTU3
  [7:5] TCR.CCLR, [4:3] TCR.CKEG, [2:0] TCR.TPSC
0x88601 MTU4
  [7:5] TCR.CCLR, [4:3] TCR.CKEG, [2:0] TCR.TPSC
0x88602 MTU3
  [5] TMDR.BFB, [4] TMDR.BFA, [3:0] TMDR.MD
0x88603 MTU4
  [5] TMDR.BFB, [4] TMDR.BFA, [3:0] TMDR.MD
0x88604 MTU3
  [7:4] TIORH.IOB, [3:0] TIORH.IOA
0x88605 MTU3
  [7:4] TIORL.IOD, [3:0] TIORL.IOC
0x88606 MTU4
  [7:4] TIORH.IOB, [3:0] TIORH.IOA
0x88607 MTU4
  [7:4] TIORL.IOD, [3:0] TIORL.IOC
0x88608 MTU3
  [7] TIER.TTGE, [4] TIER.TCIEV, [3] TIER.TGIED, [2] TIER.TGIEC, [1] TIER.TGIEB, [0] TIER.TGIEA
0x88609 MTU4
  [7] TIER.TTGE, [6] TIER.TTGE2, [4] TIER.TCIEV, [3] TIER.TGIED, [2] TIER.TGIEC, [1] TIER.TGIEB, [0] TIER.TGIEA
0x8860A MTU
  [5] TOER.OE4D, [4] TOER.OE4C, [3] TOER.OE3D, [2] TOER.OE4B, [1] TOER.OE4A, [0] TOER.OE3B
0x8860D MTU
  [6] TGCR.BDC, [5] TGCR.N, [4] TGCR.P, [3] TGCR.FB, [2] TGCR.WF, [1] TGCR.VF, [0] TGCR.UF
0x8860E MTU
  [6] TOCR1.PSYE, [3] TOCR1.TOCL, [2] TOCR1.TOCS, [1] TOCR1.OLSN, [0] TOCR1.OLSP
0x8860F MTU
  [7:6] TOCR2.BF, [5] TOCR2.OLS3N, [4] TOCR2.OLS3P, [3] TOCR2.OLS2N, [2] TOCR2.OLS2P, [1] TOCR2.OLS1N, [0] TOCR2.OLS1P
0x8862C MTU3
  [7] TSR.TCFD
0x8862D MTU4
  [7] TSR.TCFD
0x88630 MTU
  [7] TITCR.T3AEN, [6:4] TITCR.T3ACOR, [3] TITCR.T4VEN, [2:0] TITCR.T4VCOR
0x88631 MTU
  [6:4] TITCNT.T3ACNT, [2:0] TITCNT.T4VCNT
0x88632 MTU
  [1:0] TBTER.BTE
0x88634 MTU
  [0] TDER.TDER
0x88636 MTU
  [5] TOLBR.OLS3N, [4] TOLBR.OLS3P, [3] TOLBR.OLS2N, [2] TOLBR.OLS2P, [1] TOLBR.OLS1N, [0] TOLBR.OLS1P
0x88638 MTU3
  [2] TBTM.TTSE, [1] TBTM.TTSB, [0] TBTM.TTSA
0x88639 MTU4
  [2] TBTM.TTSE, [1] TBTM.TTSB, [0] TBTM.TTSA
0x88640 MTU4 16-bit
  [15:14] TADCR.BF, [7] TADCR.UT4AE, [6] TADCR.DT4AE, [5] TADCR.UT4BE, [4] TADCR.DT4BE, [3] TADCR.ITA3AE, [2] TADCR.ITA4VE, [1] TADCR.ITB3AE, [0] TADCR.ITB4VE
0x88660 MTU
  [7] TWCR.CCE, [0] TWCR.WRE
0x88680 MTU
  [7] TSTR.CST4, [6] TSTR.CST3, [2] TSTR.CST2, [1] TSTR.CST1, [0] TSTR.CST0
0x88681 MTU
  [7] TSYR.SYNC4, [6] TSYR.SYNC3, [2] TSYR.SYNC2, [1] TSYR.SYNC1, [0] TSYR.SYNC0
0x88684 MTU
  [0] TRWER.RWE
{0x88690+i} MTU{i} (i=0..4)
  fields as TPU0
0x88695 MTU5
  [5:4] NFCR.NFCS, [2] NFCR.NFWEN, [1] NFCR.NFVEN, [0] NFCR.NFUEN
0x88700 MTU0
  [7:5] TCR.CCLR, [4:3] TCR.CKEG, [2:0] TCR.TPSC
0x88701 MTU0
  [6] TMDR.BFE, [5] TMDR.BFB, [4] TMDR.BFA, [3:0] TMDR.MD
0x88702 MTU0
  [7:4] TIORH.IOB, [3:0] TIORH.IOA
0x88703 MTU0
  [7:4] TIORL.IOD, [3:0] TIORL.IOC
0x88704 MTU0
  [7] TIER.TTGE, [4] TIER.TCIEV, [3] TIER.TGIED, [2] TIER.TGIEC, [1] TIER.TGIEB, [0] TIER.TGIEA
{0x88705+0x80*i} MTU{i} (i=0..2)
  [7] TSR.TCFD
0x88724 MTU0
  [1] TIER2.TGIEF, [0] TIER2.TGIEE
0x88726 MTU0
  [2] TBTM.TTSE, [1] TBTM.TTSB, [0] TBTM.TTSA
0x88780 MTU1
  [6:5] TCR.CCLR, [4:3] TCR.CKEG, [2:0] TCR.TPSC
0x88781 MTU1
  [3:0] TMDR.MD
0x88782 MTU1
  [7:4] TIOR.IOB, [3:0] TIOR.IOA
0x88784 MTU1
  [7] TIER.TTGE, [5] TIER.TCIEU, [4] TIER.TCIEV, [1] TIER.TGIEB, [0] TIER.TGIEA
0x88790 MTU1
  [3] TICCR.I2BE, [2] TICCR.I2AE, [1] TICCR.I1BE, [0] TICCR.I1AE
0x88800 MTU2
  [6:5] TCR.CCLR, [4:3] TCR.CKEG, [2:0] TCR.TPSC
0x88801 MTU2
  [3:0] TMDR.MD
0x88802 MTU2
  [7:4] TIOR.IOB, [3:0] TIOR.IOA
0x88804 MTU2
  [7] TIER.TTGE, [5] TIER.TCIEU, [4] TIER.TCIEV, [1] TIER.TGIEB, [0] TIER.TGIEA
0x88884 MTU5
  [1:0] TCRU.TPSC
0x88886 MTU5
  [4:0] TIORU.IOC
0x88894 MTU5
  [1:0] TCRV.TPSC
0x88896 MTU5
  [4:0] TIORV.IOC
0x888A4 MTU5
  [1:0] TCRW.TPSC
0x888A6 MTU5
  [4:0] TIORW.IOC
0x888B2 MTU5
  [2] TIER.TGIE5U, [1] TIER.TGIE5V, [0] TIER.TGIE5W
0x888B4 MTU5
  [2] TSTR.CSTU5, [1] TSTR.CSTV5, [0] TSTR.CSTW5
0x888B6 MTU5
  [2] TCNTCMPCLR.CMPCLR5U, [1] TCNTCMPCLR.CMPCLR5V, [0] TCNTCMPCLR.CMPCLR5W
0x88900 POE 16-bit
  [n+12] ICSR1.POE{n}F (n=0..3), [8] ICSR1.PIE1, [2n+1:2n] ICSR1.POE{n}M (n=0..3)
0x88902 POE 16-bit
  [15] OCSR1.OSF1, [9] OCSR1.OCE1, [8] OCSR1.OIE1
0x88908 POE 16-bit
  [12] ICSR2.POE8F, [9] ICSR2.POE8E, [8] ICSR2.PIE2, [1:0] ICSR2.POE8M
0x8890A POE
  [1] SPOER.CH0HIZ, [0] SPOER.CH34HIZ
0x8890B POE
  [n] POECR1.PE{n}ZE (n=0..3)
0x8890C POE
  [6] POECR2.P1CZEA, [5] POECR2.P2CZEA, [4] POECR2.P3CZEA
0x8890E POE 16-bit
  [12] ICSR3.OSTSTF, [9] ICSR3.OSTSTE
0x89000 S12AD
  [7] ADCSR.ADST, [6] ADCSR.ADCS, [4] ADCSR.ADIE, [3:2] ADCSR.CKS, [1] ADCSR.TRGE, [0] ADCSR.EXTRG
0x89004 S12AD 16-bit
  [15:0] ADANS0.ANS0
0x89006 S12AD 16-bit
  [4:0] ADANS1.ANS1
0x89008 S12AD 16-bit
  [15:0] ADADS0.ADS0
0x8900A S12AD 16-bit
  [4:0] ADADS1.ADS1
0x8900C S12AD
  [1:0] ADADC.ADC
0x8900E S12AD 16-bit
  [15] ADCER.ADRFMT, [5] ADCER.ACE
0x89010 S12AD
  [3:0] ADSTRGR.ADSTRS
0x89012 S12AD 16-bit
  [9] ADEXICR.OCS, [8] ADEXICR.TSS, [1] ADEXICR.OCSAD, [0] ADEXICR.TSSAD
0x89060 S12AD 16-bit
  [7:0] ADSSTR01.SST1
0x89070 S12AD 16-bit
  [15:8] ADSSTR23.SST2
0x89810 AD
  [6] ADCSR.ADIE, [5] ADCSR.ADST, [2:0] ADCSR.CH
0x89811 AD
  [7:5] ADCR.TRGS, [3:2] ADCR.CKS, [1:0] ADCR.MODE
0x89812 AD
  [7] ADCR2.DPSEL, [6] ADCR2.EXOEN, [5:4] ADCR2.EXSEL
0x8981F AD
  [1:0] ADDIAGR.DIAG
{0x8A000+0x20*i} SCI{i} (i=0..11)
  [7] SMR.CM, [6] SMR.CHR, [5] SMR.PE, [4] SMR.PM, [3] SMR.STOP, [2] SMR.MP, [1:0] SMR.CKS
{0x8A000+0x20*i} SMCI{i} (i=0..11)
  [7] SMR.GM, [6] SMR.BCLK, [5] SMR.PE, [4] SMR.PM, [3:2] SMR.BCP, [1:0] SMR.CKS
{0x8A002+0x20*i} SCI{i} (i=0..11)
  [7] SCR.TIE, [6] SCR.RIE, [5] SCR.TE, [4] SCR.RE, [3] SCR.MPIE, [2] SCR.TEIE, [1:0] SCR.CKE
{0x8A002+0x20*i} SMCI{i} (i=0..11)
  [7] SCR.TIE, [6] SCR.RIE, [5] SCR.TE, [4] SCR.RE, [3] SCR.MPIE, [2] SCR.TEIE, [1:0] SCR.CKE
{0x8A004+0x20*i} SCI{i} (i=0..11)
  [5] SSR.ORER, [4] SSR.FER, [3] SSR.PER, [2] SSR.TEND, [1] SSR.MPB, [0] SSR.MPBT
{0x8A004+0x20*i} SMCI{i} (i=0..11)
  [5] SSR.ORER, [4] SSR.ERS, [3] SSR.PER, [2] SSR.TEND, [1] SSR.MPB, [0] SSR.MPBT
{0x8A006+0x20*i} SCI{i} (i=0..11)
  [7] SCMR.BCP2, [3] SCMR.SDIR, [2] SCMR.SINV, [0] SCMR.SMIF
{0x8A006+0x20*i} SMCI{i} (i=0..11)
  [7] SCMR.BCP2, [3] SCMR.SDIR, [2] SCMR.SINV, [0] SCMR.SMIF
{0x8A007+0x20*i} SCI{i} (i=0..11)
  [5] SEMR.NFEN, [4] SEMR.ABCS, [0] SEMR.ACS0
{0x8A008+0x20*i} SCI{i} (i=0..11)
  [2:0] SNFR.NFCS
{0x8A009+0x20*i} SCI{i} (i=0..11)
  [7:3] SIMR1.IICDL, [0] SIMR1.IICM
{0x8A00A+0x20*i} SCI{i} (i=0..11)
  [5] SIMR2.IICACKT, [1] SIMR2.IICCSC, [0] SIMR2.IICINTM
{0x8A00B+0x20*i} SCI{i} (i=0..11)
  [7:6] SIMR3.IICSCLS, [5:4] SIMR3.IICSDAS, [3] SIMR3.IICSTIF, [2] SIMR3.IICSTPREQ, [1] SIMR3.IICRSTAREQ, [0] SIMR3.IICSTAREQ
{0x8A00C+0x20*i} SCI{i} (i=0..11)
  [0] SISR.IICACKR
{0x8A00D+0x20*i} SCI{i} (i=0..11)
  [7] SPMR.CKPH, [6] SPMR.CKPOL, [4] SPMR.MFF, [2] SPMR.MSS, [1] SPMR.CTSE, [0] SPMR.SSE
0x8A800 IEB
  [6] IECTR.IOL, [5] IECTR.DEE, [3] IECTR.RE
0x8A801 IEB
  [2:0] IECMR.CMD
0x8A802 IEB
  [7] IEMCR.SS, [6:4] IEMCR.RN, [3:0] IEMCR.CTL
0x8A803 IEB
  [7:4] IEAR1.IARL4, [3:2] IEAR1.IMD, [0] IEAR1.STE
0x8A804 IEB
  [7:0] IEAR2.IARU8
0x8A805 IEB
  [7:4] IESA1.ISAL4
0x8A806 IEB
  [7:0] IESA2.ISAU8
0x8A807 IEB
  [7:0] IETBFL.IBFL
0x8A809 IEB
  [7:4] IEMA1.IMAL4
0x8A80A IEB
  [7:0] IEMA2.IMAU8
0x8A80B IEB
  [3:0] IERCTL.RCTL
0x8A80C IEB
  [7:0] IERBFL.RBFL
0x8A80E IEB
  [7:0] IELA1.ILAL8
0x8A80F IEB
  [3:0] IELA2.ILAU4
0x8A810 IEB
  [7] IEFLG.CMX, [6] IEFLG.MRQ, [5] IEFLG.SRQ, [4] IEFLG.SRE, [3] IEFLG.LCK, [1] IEFLG.RSS, [0] IEFLG.GG
0x8A811 IEB
  [6] IETSR.TXS, [5] IETSR.TXF, [3] IETSR.TXEAL, [2] IETSR.TXETTME, [1] IETSR.TXERO, [0] IETSR.TXEACK
0x8A812 IEB
  [6] IEIET.TXSE, [5] IEIET.TXFE, [3] IEIET.TXEALE, [2] IEIET.TXETTMEE, [1] IEIET.TXEROE, [0] IEIET.TXEACKE
0x8A814 IEB
  [7] IERSR.RXBSY, [6] IERSR.RXS, [5] IERSR.RXF, [4] IERSR.RXEDE, [3] IERSR.RXEOVE, [2] IERSR.RXERTME, [1] IERSR.RXEDLE, [0] IERSR.RXEPE
0x8A815 IEB
  [7] IEIER.RXBSYE, [6] IEIER.RXSE, [5] IEIER.RXFE, [4] IEIER.RXEDEE, [3] IEIER.RXEOVEE, [2] IEIER.RXERTMEE, [1] IEIER.RXEDLEE, [0] IEIER.RXEPEE
0x8A818 IEB
  [7] IECKSR.FLT, [6:5] IECKSR.FCKS, [4] IECKSR.CKS3, [3] IECKSR.SRSTP, [2:0] IECKSR.CKS
0x8B300 SCI12
  fields as SCI0
0x8B300 SMCI12
  fields as SMCI0
0x8B302 SCI12
  [7] SCR.TIE, [6] SCR.RIE, [5] SCR.TE, [4] SCR.RE, [3] SCR.MPIE, [2] SCR.TEIE, [1:0] SCR.CKE
0x8B302 SMCI12
  [7] SCR.TIE, [6] SCR.RIE, [5] SCR.TE, [4] SCR.RE, [3] SCR.MPIE, [2] SCR.TEIE, [1:0] SCR.CKE
0x8B304 SCI12
  [5] SSR.ORER, [4] SSR.FER, [3] SSR.PER, [2] SSR.TEND, [1] SSR.MPB, [0] SSR.MPBT
0x8B304 SMCI12
  [5] SSR.ORER, [4] SSR.ERS, [3] SSR.PER, [2] SSR.TEND, [1] SSR.MPB, [0] SSR.MPBT
0x8B306 SCI12
  [7] SCMR.BCP2, [3] SCMR.SDIR, [2] SCMR.SINV, [0] SCMR.SMIF
0x8B306 SMCI12
  [7] SCMR.BCP2, [3] SCMR.SDIR, [2] SCMR.SINV, [0] SCMR.SMIF
0x8B307 SCI12
  [5] SEMR.NFEN, [4] SEMR.ABCS, [0] SEMR.ACS0
0x8B308 SCI12
  [2:0] SNFR.NFCS
0x8B309 SCI12
  [7:3] SIMR1.IICDL, [0] SIMR1.IICM
0x8B30A SCI12
  [5] SIMR2.IICACKT, [1] SIMR2.IICCSC, [0] SIMR2.IICINTM
0x8B30B SCI12
  [7:6] SIMR3.IICSCLS, [5:4] SIMR3.IICSDAS, [3] SIMR3.IICSTIF, [2] SIMR3.IICSTPREQ, [1] SIMR3.IICRSTAREQ, [0] SIMR3.IICSTAREQ
0x8B30C SCI12
  [0] SISR.IICACKR
0x8B30D SCI12
  [7] SPMR.CKPH, [6] SPMR.CKPOL, [4] SPMR.MFF, [2] SPMR.MSS, [1] SPMR.CTSE, [0] SPMR.SSE
0x8B320 SCI12
  [0] ESMER.ESME
0x8B321 SCI12
  [3] CR0.BRME, [2] CR0.RXDSF, [1] CR0.SFSF
0x8B322 SCI12
  [7:5] CR1.PIBS, [4] CR1.PIBE, [3:2] CR1.CF1DS, [1] CR1.CF0RE, [0] CR1.BFE
0x8B323 SCI12
  [7:6] CR2.RTS, [5:4] CR2.BCCS, [2:0] CR2.DFCS
0x8B324 SCI12
  [0] CR3.SDST
0x8B325 SCI12
  [4] PCR.SHARPS, [1] PCR.RXDXPS, [0] PCR.TXDXPS
0x8B326 SCI12
  [5] ICR.AEDIE, [4] ICR.BCDIE, [3] ICR.PIBDIE, [2] ICR.CF1MIE, [1] ICR.CF0MIE, [0] ICR.BFDIE
0x8B327 SCI12
  [5] STR.AEDF, [4] STR.BCDF, [3] STR.PIBDF, [2] STR.CF1MF, [1] STR.CF0MF, [0] STR.BFDF
0x8B328 SCI12
  [5] STCR.AEDCL, [4] STCR.BCDCL, [3] STCR.PIBDCL, [2] STCR.CF1MCL, [1] STCR.CF0MCL, [0] STCR.BFDCL
0x8B32A SCI12
  [n] CF0CR.CF0CE{n} (n=0..7)
0x8B32E SCI12
  [n] CF1CR.CF1CE{n} (n=0..7)
0x8B330 SCI12
  [0] TCR.TCST
0x8B331 SCI12
  [6:4] TMR.TCSS, [3] TMR.TWRC, [1:0] TMR.TOMS
0x8C000 PORT0
  [7] PDR.B7, [5] PDR.B5, [n] PDR.B{n} (n=0..3)
0x8C001 PORT1
  [n] PDR.B{n} (n=0..7)
0x8C002 PORT2
  [n] PDR.B{n} (n=0..7)
0x8C003 PORT3
  [7] PDR.B7, [6] PDR.B6, [n] PDR.B{n} (n=0..4)
{0x8C000+i} PORT{i} (i=4..9)
  [n] PDR.B{n} (n=0..7)
0x8C00A PORTA
  [n] PDR.B{n} (n=0..7)
0x8C00B PORTB
  [n] PDR.B{n} (n=0..7)
0x8C00C PORTC
  [n] PDR.B{n} (n=0..7)
0x8C00D PORTD
  [n] PDR.B{n} (n=0..7)
0x8C00E PORTE
  [n] PDR.B{n} (n=0..7)
0x8C00F PORTF
  [n] PDR.B{n} (n=0..5)
0x8C010 PORTG
  [n] PDR.B{n} (n=0..7)
0x8C012 PORTJ
  [5] PDR.B5, [3] PDR.B3
0x8C020 PORT0
  [7] PODR.B7, [5] PODR.B5, [n] PODR.B{n} (n=0..3)
0x8C021 PORT1
  [n] PODR.B{n} (n=0..7)
0x8C022 PORT2
  [n] PODR.B{n} (n=0..7)
0x8C023 PORT3
  [7] PODR.B7, [6] PODR.B6, [n] PODR.B{n} (n=0..4)
{0x8C020+i} PORT{i} (i=4..9)
  [n] PODR.B{n} (n=0..7)
0x8C02A PORTA
  [n] PODR.B{n} (n=0..7)
0x8C02B PORTB
  [n] PODR.B{n} (n=0..7)
0x8C02C PORTC
  [n] PODR.B{n} (n=0..7)
0x8C02D PORTD
  [n] PODR.B{n} (n=0..7)
0x8C02E PORTE
  [n] PODR.B{n} (n=0..7)
0x8C02F PORTF
  [n] PODR.B{n} (n=0..5)
0x8C030 PORTG
  [n] PODR.B{n} (n=0..7)
0x8C032 PORTJ
  [5] PODR.B5, [3] PODR.B3
0x8C040 PORT0
  [7] PIDR.B7, [5] PIDR.B5, [n] PIDR.B{n} (n=0..3)
{0x8C040+i} PORT{i} (i=1..9)
  [n] PIDR.B{n} (n=0..7)
0x8C04A PORTA
  [n] PIDR.B{n} (n=0..7)
0x8C04B PORTB
  [n] PIDR.B{n} (n=0..7)
0x8C04C PORTC
  [n] PIDR.B{n} (n=0..7)
0x8C04D PORTD
  [n] PIDR.B{n} (n=0..7)
0x8C04E PORTE
  [n] PIDR.B{n} (n=0..7)
0x8C04F PORTF
  [n] PIDR.B{n} (n=0..5)
0x8C050 PORTG
  [n] PIDR.B{n} (n=0..7)
0x8C052 PORTJ
  [5] PIDR.B5, [3] PIDR.B3
0x8C060 PORT0
  [7] PMR.B7, [5] PMR.B5, [n] PMR.B{n} (n=0..3)
{0x8C060+i} PORT{i} (i=1..9)
  [n] PMR.B{n} (n=0..7)
0x8C06A PORTA
  [n] PMR.B{n} (n=0..7)
0x8C06B PORTB
  [n] PMR.B{n} (n=0..7)
0x8C06C PORTC
  [n] PMR.B{n} (n=0..7)
0x8C06D PORTD
  [n] PMR.B{n} (n=0..7)
0x8C06E PORTE
  [n] PMR.B{n} (n=0..7)
0x8C06F PORTF
  [n] PMR.B{n} (n=0..5)
0x8C070 PORTG
  [n] PMR.B{n} (n=0..7)
0x8C072 PORTJ
  [5] PMR.B5, [3] PMR.B3
0x8C080 PORT0
  [6] ODR0.B6, [4] ODR0.B4, [2] ODR0.B2, [0] ODR0.B0
0x8C081 PORT0
  [6] ODR1.B6, [2] ODR1.B2
0x8C082 PORT1
  [6] ODR0.B6, [4] ODR0.B4, [2] ODR0.B2, [0] ODR0.B0
0x8C083 PORT1
  [6] ODR1.B6, [4] ODR1.B4, [2] ODR1.B2, [0] ODR1.B0
0x8C084 PORT2
  [6] ODR0.B6, [4] ODR0.B4, [2] ODR0.B2, [0] ODR0.B0
